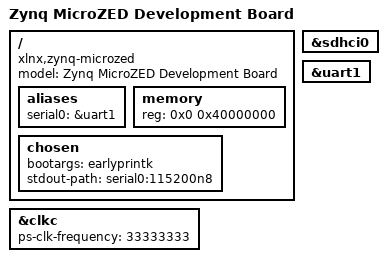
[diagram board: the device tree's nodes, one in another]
/*
 * Copyright (C) 2015 Jagan Teki <jteki@openedev.com>
 *
 * This software is licensed under the terms of the GNU General Public
 * License version 2, as published by the Free Software Foundation, and
 * may be copied, distributed, and modified under those terms.
 *
 * This program is distributed in the hope that it will be useful,
 * but WITHOUT ANY WARRANTY; without even the implied warranty of
 * MERCHANTABILITY or FITNESS FOR A PARTICULAR PURPOSE.  See the
 * GNU General Public License for more details.
 */
/dts-v1/;
/include/ "zynq-7000.dtsi"

/ {
	model = "Zynq MicroZED Development Board";
	compatible = "xlnx,zynq-microzed", "xlnx,zynq-7000";

	aliases {
		serial0 = &uart1;
	};

	memory {
		device_type = "memory";
		reg = <0x0 0x40000000>;
	};

	chosen {
		bootargs = "earlyprintk";
		stdout-path = "serial0:115200n8";
	};
};

&clkc {
	ps-clk-frequency = <33333333>;
};

&sdhci0 {
	status = "okay";
};

&uart1 {
	status = "okay";
};
